# N575F145_v1 register map
File version: 1.0
Registers are 32-bit, read-write, reset 0x0 unless marked. A register's access mark holds for its fields unless they carry their own. Offsets are from the block's base; [hi:lo] are bit positions.

## RTC — RTC Register Map
Base 0x40008000
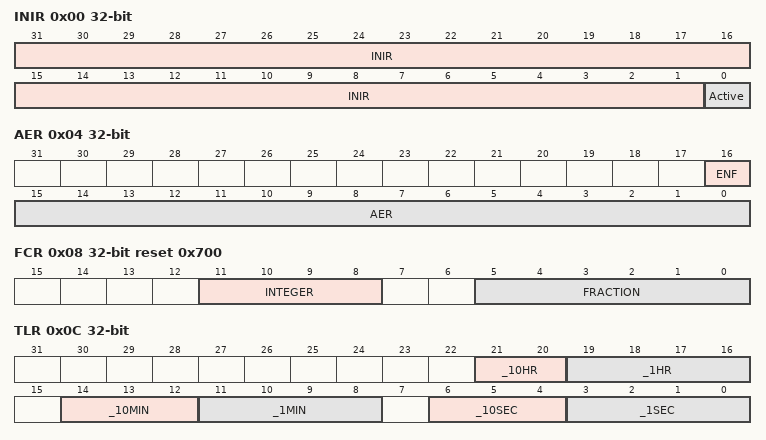
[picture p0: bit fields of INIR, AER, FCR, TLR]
0x00 INIR — RTC Initialization Register
  [31:1] INIR — RTC Initialization. After a power-on reset (POR) RTC block should be initialized by writing 0xA5EB1357 to INIR. This will force a hardware reset then release all logic and counters.
  [0] Active ro — RTC Active Status (Read only). 0: RTC is in reset state. 1: RTC is in normal active state.
0x04 AER — RTC Access Enable Register
  [16] ENF ro — RTC Register Access Enable Flag (Read only). This bit will be set after AER[15:0] register is set to 0xA965, it will clear automatically in 512 RTC clock cycles or AER[15:0] ! = 0xA965. The effect of AER.ENF on access to each register is given Table 572. Table 572 AER.ENF Register Access Effect. Register : ENF = 1 : ENF = 0. INIR : R/W : R/W. FCR : R/W : - TLR : R/W : R. CLR : R/W : R. TSSR : R/W : R/W. DWR : R/W : R. TAR : R/W : - CAR : R/W : - LIR : R : R. RIER : R/W : R/W. RIIR : R/W : R/W. TTR : R/W : -
    0=RTC register read/write disable; 1=RTC register read/write enable
  [15:0] AER wo — RTC Register Access Enable Password (Write only). 0xA965 = Enable RTC access. Others = Disable RTC access
0x08 FCR reset 0x700 — RTC Frequency Compensation Register
  [11:8] INTEGER — Integer Part. Register should contain the value (INT(Factual) - 32761). Ex: Integer part of detected value = 32772, FCR.INTEGER = 32772-32761 = 11 (1011b). The range between 32761 and 32776
  [5:0] FRACTION — Fractional Part. Formula = (fraction part of detected value) x 60. Refer to 5.8.4.4 for the examples.
0x0C TLR — Time Load Register
  [21:20] _10HR — 10 Hour Time Digit (0~3)
  [19:16] _1HR — 1 Hour Time Digit (0~9)
  [14:12] _10MIN — 10 Min Time Digit (0~5)
  [11:8] _1MIN — 1 Min Time Digit (0~9)
  [6:4] _10SEC — 10 Sec Time Digit (0~5)
  [3:0] _1SEC — 1 Sec Time Digit (0~9)
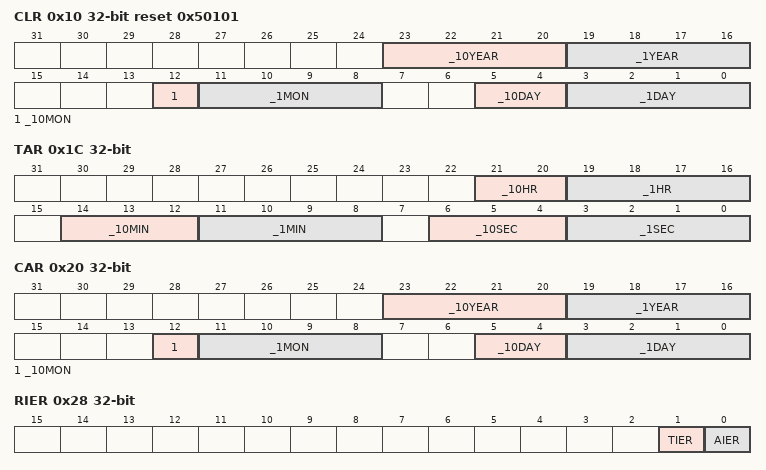
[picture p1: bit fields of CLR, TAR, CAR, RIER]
0x10 CLR reset 0x50101 — Calendar Load Register
  [23:20] _10YEAR — 10-Year Calendar Digit (0~9)
  [19:16] _1YEAR — 1-Year Calendar Digit (0~9)
  [12] _10MON — 10-Month Calendar Digit (0~1)
  [11:8] _1MON — 1-Month Calendar Digit (0~9)
  [5:4] _10DAY — 10-Day Calendar Digit (0~3)
  [3:0] _1DAY — 1-Day Calendar Digit (0~9)
0x14 TSSR reset 0x1 — Time Scale Selection Register
  [0] HR24 — 24-Hour / 12-Hour Mode Selection. Determines whether TLR and TAR are in 24-hour mode or 12-hour mode . The range of 24-hour time scale is between 0 and 23. 12-hour time scale: 01(AM01), 02(AM02), 03(AM03), 04(AM04), 05(AM05), 06(AM06). 07(AM07), 08(AM08), 09(AM09), 10(AM10), 11(AM11), 12(AM12). 21(PM01), 22(PM02), 23(PM03), 24(PM04), 25(PM05), 26(PM06). 27(PM07), 28(PM08), 29(PM09), 30(PM10), 31(PM11), 32(PM12)
    0=select 12-hour time scale with AM and PM indication; 1=select 24-hour time scale
0x18 DWR reset 0x6 — Day of the Week Register
  [2:0] DWR — Day of the Week Register. 0 (Sunday), 1 (Monday), 2 (Tuesday), 3 (Wednesday). 4 (Thursday), 5 (Friday), 6 (Saturday)
0x1C TAR — Time Alarm Register
  [21:20] _10HR — 10 Hour Time Digit of Alarm Setting (0~3)
  [19:16] _1HR — 1 Hour Time Digit of Alarm Setting (0~9)
  [14:12] _10MIN — 10 Min Time Digit of Alarm Setting (0~5)
  [11:8] _1MIN — 1 Min Time Digit of Alarm Setting (0~9)
  [6:4] _10SEC — 10 Sec Time Digit of Alarm Setting (0~5)
  [3:0] _1SEC — 1 Sec Time Digit of Alarm Setting (0~9)
0x20 CAR — Calendar Alarm Register
  [23:20] _10YEAR — 10-Year Calendar Digit of Alarm Setting (0~9)
  [19:16] _1YEAR — 1-Year Calendar Digit of Alarm Setting (0~9)
  [12] _10MON — 10-Month Calendar Digit of Alarm Setting (0~1)
  [11:8] _1MON — 1-Month Calendar Digit of Alarm Setting (0~9)
  [5:4] _10DAY — 10-Day Calendar Digit of Alarm Setting (0~3)
  [3:0] _1DAY — 1-Day Calendar Digit of Alarm Setting (0~9)
0x24 LIR ro — Leap year Indicator Register
  [0] LIR — Leap Year Indication Register (read only)
    0=Current year is not a leap year; 1=Current year is leap year
0x28 RIER — RTC Interrupt Enable Register
  [1] TIER — Time-Tick Interrupt and Wakeup-by-Tick Enable
    0=RTC Time-Tick Interrupt is disabled; 1=RTC Time-Tick Interrupt is enabled
  [0] AIER — Alarm Interrupt Enable
    0=RTC Alarm Interrupt is disabled; 1=RTC Alarm Interrupt is enabled
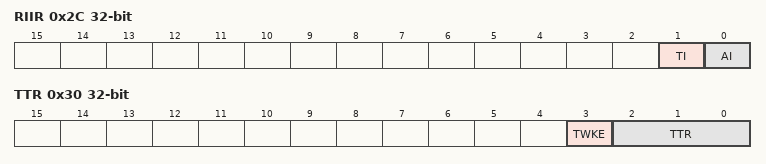
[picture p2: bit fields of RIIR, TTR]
0x2C RIIR — RTC Interrupt Indicator Register
  [1] TI — RTC Time-Tick Interrupt Flag
    0=Indicates no Time-Tick Interrupt condition; 1=Indicates RTC Time-Tick Interrupt generated
  [0] AI — RTC Alarm Interrupt Flag
    0=Indicates no Alarm Interrupt condition; 1=Indicates RTC Alarm Interrupt generated
0x30 TTR — RTC Time Tick Register
  [3] TWKE — RTC Timer Wakeup CPU Function Enable Bit. If TWKE is set before CPU is in power-down mode, when a RTC Time-Tick or Alarm Match occurs, CPU will wake up.
    0=Disable Wakeup CPU function; 1=Enable the Wakeup function
  [2:0] TTR — Time Tick Register. The RTC time tick period for Periodic Time-Tick Interrupt request. Time Tick (second) : 1 / (2^TTR). Note: This register can be read back after the RTC is active.
